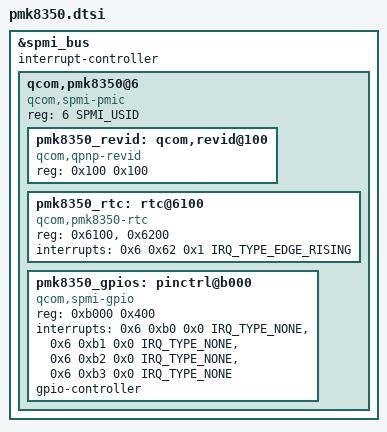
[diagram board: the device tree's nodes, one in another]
#include <dt-bindings/interrupt-controller/irq.h>
#include <dt-bindings/spmi/spmi.h>

&spmi_bus {
	#address-cells = <2>;
	#size-cells = <0>;
	interrupt-controller;
	#interrupt-cells = <4>;

	qcom,pmk8350@6 {
		compatible = "qcom,spmi-pmic";
		reg = <6 SPMI_USID>;
		#address-cells = <1>;
		#size-cells = <1>;

		pmk8350_revid: qcom,revid@100 {
			compatible = "qcom,qpnp-revid";
			reg = <0x100 0x100>;
		};

		pmk8350_rtc: rtc@6100 {
			compatible = "qcom,pmk8350-rtc";
			reg = <0x6100>, <0x6200>;
			reg-names = "rtc", "alarm";
			interrupts = <0x6 0x62 0x1 IRQ_TYPE_EDGE_RISING>;
		};

		pmk8350_gpios: pinctrl@b000 {
			compatible = "qcom,spmi-gpio";
			reg = <0xb000 0x400>;
			interrupts = <0x6 0xb0 0x0 IRQ_TYPE_NONE>,
				     <0x6 0xb1 0x0 IRQ_TYPE_NONE>,
				     <0x6 0xb2 0x0 IRQ_TYPE_NONE>,
				     <0x6 0xb3 0x0 IRQ_TYPE_NONE>;
			interrupt-names = "pmk8350_gpio1", "pmk8350_gpio2",
					"pmk8350_gpio3", "pmk8350_gpio4";
			gpio-controller;
			#gpio-cells = <2>;
		};
	};
};
